# PIC32CZ8110CA90100 device description
Architecture: CORTEX-M7; Family: PIC32C; Series: PIC32CZCA90
Registers are 32-bit, read-write, reset 0x0 unless marked. A register's access mark holds for its fields unless they carry their own. Offsets are from the block's base; [hi:lo] are bit positions; {n}, {i} and the like mark numbered series.

## FUSES_DALCFG — Defines FUSE parameters
Instances: FUSES_DALCFG 0x0A004000
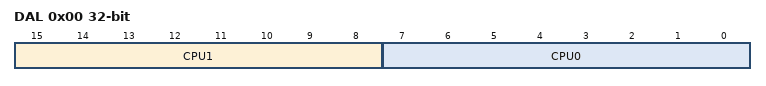
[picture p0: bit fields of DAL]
0x00 DAL — Debug Access Level
  [15:8] CPU1 — HSM DAL Elevation Value
    129=DAL0; 153=DAL1; 219=DAL2
  [7:0] CPU0 — Host DAL Elevation Value
    129=DAL0 (FCW_DAL0_VALUE); 153=DAL1 (FCW_DAL1_VALUE); 219=DAL2 (FCW_DAL2_VALUE)

## FUSES_USERCFG1 — Defines FUSE parameters
Instances: FUSES_USERCFG1 0x0A000000, FUSES_USERCFG2 0x0A008000
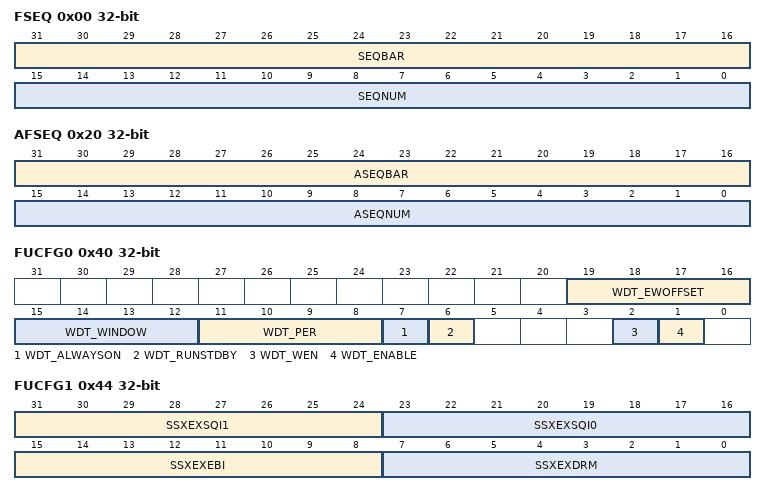
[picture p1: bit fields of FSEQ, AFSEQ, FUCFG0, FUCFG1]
0x00 FSEQ reset not defined — Flash Sequence Number
  [31:16] SEQBAR — Sequence Number Bar (Negeated)
  [15:0] SEQNUM — Sequence Number
0x20 AFSEQ reset not defined — Flash Alternate Sequence Number
  [31:16] ASEQBAR — Alternate Sequence Number Bar (Negeated)
  [15:0] ASEQNUM — Alternate Sequence Number
0x40 FUCFG0 reset not defined — WDT Configuration
  [19:16] WDT_EWOFFSET — Early Warning Interrupt Time Offset
  [15:12] WDT_WINDOW — Window Mode Time-out Period
  [11:8] WDT_PER — Time-out Period
  [7] WDT_ALWAYSON — Always On
  [6] WDT_RUNSTDBY — Run in Standby
  [2] WDT_WEN — Window Mode Enable
  [1] WDT_ENABLE — Enable
0x44 FUCFG1 reset not defined — User Configuration 1 (System Bus Configuration)
  [31:24] SSXEXSQI1 — Execute from SQI1 XIP Memory
  [23:16] SSXEXSQI0 — Execute from SQI0 XIP Memory
  [15:8] SSXEXEBI — Execute from EBI attached Memory
  [7:0] SSXEXDRM — Execute from System Memory
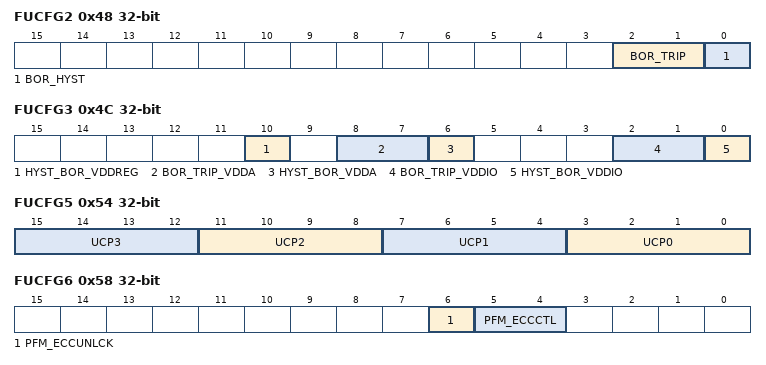
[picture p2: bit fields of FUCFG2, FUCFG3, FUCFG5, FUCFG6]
0x48 FUCFG2 reset not defined — User Configuration 2 (Deep Sleep SMOR Configuration)
  [2:1] BOR_TRIP — BOT Trip Points
  [0] BOR_HYST — BOT Trip Hystersis
0x4C FUCFG3 reset not defined — User Configuration 2 (SMOR Configuration)
  [10] HYST_BOR_VDDREG — BOR Trip Point Hystersis for VDDREG
  [8:7] BOR_TRIP_VDDA — BOR Trip Points for VDDANA
  [6] HYST_BOR_VDDA — BOR Trip Point Hystersis for VDDANA
  [2:1] BOR_TRIP_VDDIO — BOR Trip Points for VDDIO
  [0] HYST_BOR_VDDIO — BOR Trip Point Hystersis for VDDIO
0x54 FUCFG5 — User Configuration 5 (VREG Charge Pump Configuration)
  [4n+3:4n] UCP{n} (n=0..3) — Charge Pump Settings
0x58 FUCFG6 reset not defined — User Configuration 6 (FCR ECCCTRL Configuration)
  [6] PFM_ECCUNLCK — ECC Mode Control Unlock
  [5:4] PFM_ECCCTL — ECC Mode Control
0x5C FUCFG7 reset not defined — User Configuration 7 (FCR CTRLB Configuration)
  [1] PFM_TEMP — NVM Operating Temperature Read Mode
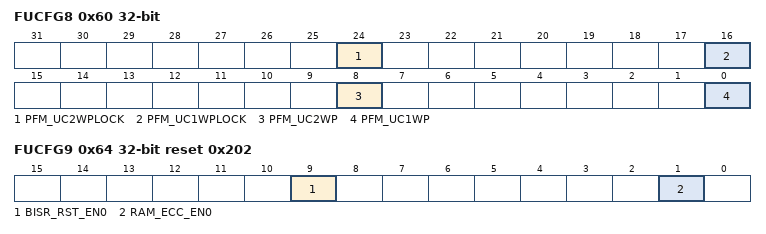
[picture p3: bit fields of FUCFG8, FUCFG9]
0x60 FUCFG8 reset not defined — User Configuration 8 (FCW CWP Configuration)
  [24] PFM_UC2WPLOCK — User Configuration Page 2 Write Protection Lock
  [16] PFM_UC1WPLOCK — User Configuration Page 1 Write Protection Lock
  [8] PFM_UC2WP — User Configuration Page 2 Write Protect
  [0] PFM_UC1WP — User Configuration Page 1 Write Protect
0x64 FUCFG9 reset 0x202 — User Configuration 9 (RAM BISR and ECC Configuraiton)
  [9] BISR_RST_EN0 — Enable RAM Built-In Self Repair at Reset
  [1] RAM_ECC_EN0 — Enable RAM ECC Control at Reset
0x80 FUCFG16 reset not defined — User Configuration 16 (HSM Firmware Metadata 0 Address)
  [31:0] HSM_PTRMETA0 — HSM Firmware Metadata pointer 0
0xA0 FUCFG24 reset not defined — User Configuration 24 (HSM Firmware Metadata 1 Address)
  [31:0] HSM_PTRMETA1 — HSM Firmware Metadata pointer 1

## GCLK — Generic Clock Generator
Instances: GCLK 0x44050000
0x00 CTRLA 8-bit (WSYNC) — Control
  [0] SWRST — Software Reset
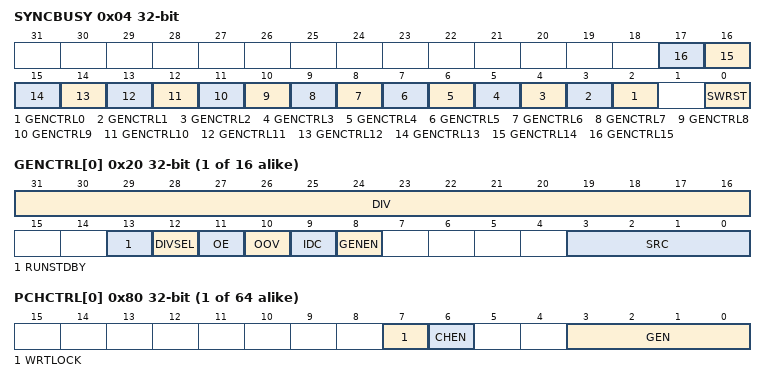
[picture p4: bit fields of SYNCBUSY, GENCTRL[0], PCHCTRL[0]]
0x04 SYNCBUSY ro — Synchronization Busy
  [n+2] GENCTRL{n} (n=0..15) — Generic Clock Generator Control {n} Synchronization Busy bit
  [0] SWRST — Software Reset Synchronization Busy bit
{0x20+4i} GENCTRL[{i}] (i=0..15) (WSYNC) — Generic Clock Generator Control
  [31:16] DIV — Division Factor
  [13] RUNSTDBY — Run in Standby
  [12] DIVSEL — Divide Selection
    0=DIV1 (Divide input directly by divider factor); 1=DIV2 (Divide input by 2^(divider factor+ 1))
  [11] OE — Output Enable
  [10] OOV — Output Off Value
  [9] IDC — Improve Duty Cycle
  [8] GENEN — Generic Clock Generator Enable
  [3:0] SRC — Source Select
    0=XOSC (XOSC0 oscillator output); 1=GCLKIN (Generator input pad); 2=GCLKGEN1 (Generic clock generator 1 output); 3=OSCULP32K (OSCULP32K oscillator output); 4=XOSC32K (XOSC32K oscillator output); 5=DFLL (DFLL output); {v}=PLL0_{v-5} (PLL0 output {v-5}) (v=6..9); 10=PLL1_1 (Frac Divider PLL1 output 1); 11=PLL1_2 (Frac Divider PLL1 output 2); 12=PLL1_3 (PLL1 output 3); 13=PLL1_4 (PLL1 output 4)
{0x80+4i} PCHCTRL[{i}] (i=0..63) — Peripheral Clock Control
  [7] WRTLOCK — Write Lock
  [6] CHEN — Channel Enable
  [3:0] GEN — Generic Clock Generator
    {v}=GCLK{v} (Generic clock generator {v}) (v=0..15)

## Notices in the file
Copyright (c) 2021 Microchip Technology Inc.
SPDX-License-Identifier: Apache-2.0
Licensed under the Apache License, Version 2.0 (the "License");
you may not use this file except in compliance with the License.
You may obtain a copy of the License at
http://www.apache.org/licenses/LICENSE-2.0
Unless required by applicable law or agreed to in writing, software
distributed under the License is distributed on an "AS IS" BASIS,
WITHOUT WARRANTIES OR CONDITIONS OF ANY KIND, either express or implied.
See the License for the specific language governing permissions and
limitations under the License.
